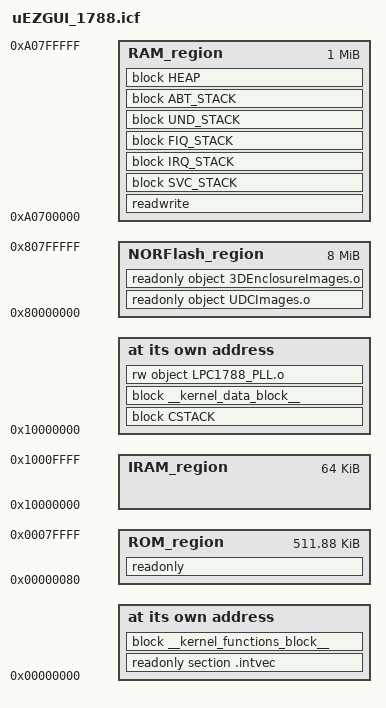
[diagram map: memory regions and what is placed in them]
/*###ICF### Section handled by ICF editor, don't touch! ****/
/*-Editor annotation file-*/
/* IcfEditorFile="$TOOLKIT_DIR$\config\ide\IcfEditor\a_v1_0.xml" */
/*-Specials-*/
define symbol __ICFEDIT_intvec_start__ = 0x00000000;
/*-Memory Regions-*/
define symbol __ICFEDIT_region_ROM_start__ = 0x00000080;
define symbol __ICFEDIT_region_ROM_end__   = 0x0007FFFF;
define symbol __ICFEDIT_region_RAM_start__ = 0xA0700000;
define symbol __ICFEDIT_region_RAM_end__   = 0xA07FFFFF;
/*-Sizes-*/
define symbol __ICFEDIT_size_cstack__   = 0x400;
define symbol __ICFEDIT_size_svcstack__ = 0x10;
define symbol __ICFEDIT_size_irqstack__ = 0x100;
define symbol __ICFEDIT_size_fiqstack__ = 0x100;
define symbol __ICFEDIT_size_undstack__ = 0x10;
define symbol __ICFEDIT_size_abtstack__ = 0x10;
define symbol __ICFEDIT_size_heap__     = 500000;
/**** End of ICF editor section. ###ICF###*/

/* USe the SRAM for the system stack and the kernel data. */
define symbol __ICFEDIT_region_IRAM_start__ = 0x10000000;
define symbol __ICFEDIT_region_IRAM_end__   = 0x1000FFFF;
define symbol __ICFEDIT_region_NORFlash_start__ = 0x80000000;
define symbol __ICFEDIT_region_NORFlash_end__   = 0x807FFFFF;


/* This must match the number of implemented vectors * 4 and be padded to an 8
byte boundary (check the mapfile to ensure that the kernel function region is 
correctly occupying the first 8K region of flash). There does not seem to be any 
way of dynamically determining the size of the vector table section at link time, 
hence this direct definition. */
define symbol __size_vectors__              = 0xE8;

define memory mem with size = 4G;
define region ROM_region   = mem:[from __ICFEDIT_region_ROM_start__   to __ICFEDIT_region_ROM_end__];
define region RAM_region   = mem:[from __ICFEDIT_region_RAM_start__   to __ICFEDIT_region_RAM_end__];
define region IRAM_region   = mem:[from __ICFEDIT_region_IRAM_start__   to __ICFEDIT_region_IRAM_end__];
define region NORFlash_region   = mem:[from __ICFEDIT_region_NORFlash_start__   to __ICFEDIT_region_NORFlash_end__];


define block CSTACK    with alignment = 8, size = __ICFEDIT_size_cstack__   { };
define block SVC_STACK with alignment = 8, size = __ICFEDIT_size_svcstack__ { };
define block IRQ_STACK with alignment = 8, size = __ICFEDIT_size_irqstack__ { };
define block FIQ_STACK with alignment = 8, size = __ICFEDIT_size_fiqstack__ { };
define block UND_STACK with alignment = 8, size = __ICFEDIT_size_undstack__ { };
define block ABT_STACK with alignment = 8, size = __ICFEDIT_size_abtstack__ { };
define block HEAP      with alignment = 8, size = __ICFEDIT_size_heap__     { };

initialize by copy { readwrite };
do not initialize  { section .noinit };

/* Define a block for the kernel's functions.  - __size_vectors__ because the 
first part of the 8K is taken by the interrupt vectors. */
define block __kernel_functions_block__ with alignment = 8, size = 0x2000 - __size_vectors__ { section __kernel_functions__ };

/* Place the interrupt vectors at the required address, followed by the kernel's
functions. */
place at address mem:__ICFEDIT_intvec_start__ { readonly section .intvec, block __kernel_functions_block__ };

/* Define a block for the kernel's data. */
define block __kernel_data_block__ with alignment = 0x400, size = 0x400 { section __kernel_data__ };

/* Place the main stack at the start of IRAM, followed by the kernel's data. */
place at address mem:__ICFEDIT_region_IRAM_start__  { block CSTACK, block __kernel_data_block__, rw object LPC1788_PLL.o };

place in ROM_region   { readonly };
place in NORFlash_region   { readonly object UDCImages.o,
                             readonly object 3DEnclosureImages.o};
place in RAM_region   { readwrite,
                        block SVC_STACK, block IRQ_STACK, block FIQ_STACK,
                        block UND_STACK, block ABT_STACK, block HEAP };
                        
/* Export symbols required by c code. */
export symbol __ICFEDIT_intvec_start__;
export symbol __ICFEDIT_size_cstack__;
export symbol __ICFEDIT_region_ROM_start__;
export symbol __ICFEDIT_region_ROM_end__;       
